# RSS_CTRL register map
Vendor: Texas Instruments
Peripheral module from a debugger description file (folder awr29xx).
Registers are 32-bit, read-only, no defined reset value unless marked. A register's access mark holds for its fields unless they carry their own. Offsets are as the file gives them; lines under a group give offsets from that group; [hi:lo] are bit positions; {n}, {i} and the like mark numbered series; 'fields as' and 'values as' point back to an identical list; <NAME> marks a mode.

## RSS_CTRL
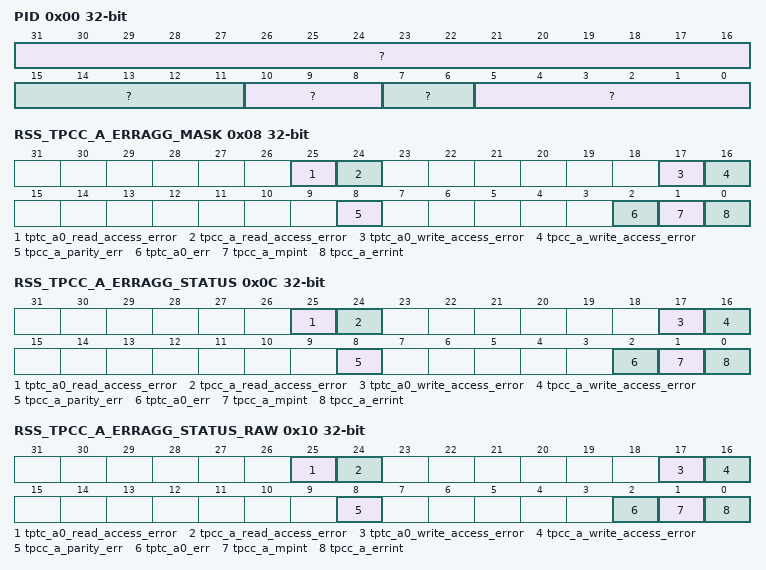
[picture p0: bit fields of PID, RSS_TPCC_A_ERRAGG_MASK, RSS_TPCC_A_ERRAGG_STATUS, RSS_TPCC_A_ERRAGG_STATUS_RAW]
0x00 PID
  [31:16] ?, [15:11] ?, [10:8] ?, [7:6] ?, [5:0] ?
0x08 RSS_TPCC_A_ERRAGG_MASK rw
  [25] tptc_a0_read_access_error, [24] tpcc_a_read_access_error, [17] tptc_a0_write_access_error, [16] tpcc_a_write_access_error, [8] tpcc_a_parity_err, [2] tptc_a0_err, [1] tpcc_a_mpint, [0] tpcc_a_errint
0x0C RSS_TPCC_A_ERRAGG_STATUS rw
  fields as RSS_TPCC_A_ERRAGG_MASK
0x10 RSS_TPCC_A_ERRAGG_STATUS_RAW rw
  fields as RSS_TPCC_A_ERRAGG_MASK
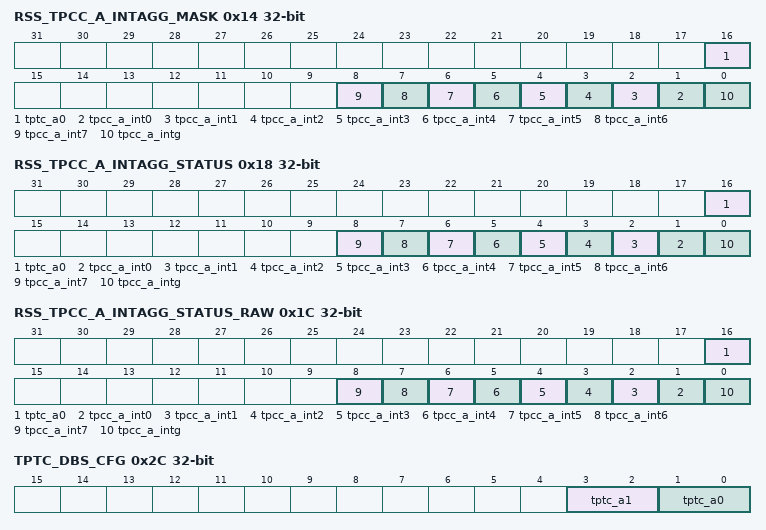
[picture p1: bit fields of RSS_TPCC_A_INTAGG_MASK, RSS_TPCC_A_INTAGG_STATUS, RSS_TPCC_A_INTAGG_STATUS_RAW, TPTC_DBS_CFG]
0x14 RSS_TPCC_A_INTAGG_MASK rw
  [16] tptc_a0 — Mask Interrupt from TPTC A0 to aggregated Interrupt RCSS_TPCC_A_INTAGG 1 : Interrupt is Masked 0 : Interrupt is Unmasked
  [n+1] tpcc_a_int{n} (n=0..7)
  [0] tpcc_a_intg
0x18 RSS_TPCC_A_INTAGG_STATUS rw
  [16] tptc_a0 — Status of Interrupt from TPTC A0. Set only if Interupt is unmasked in RCSS_TPCC_A_INTAGG_MASK Wrie 0x1 to clear this interrupt.
  [n+1] tpcc_a_int{n} (n=0..7)
  [0] tpcc_a_intg
0x1C RSS_TPCC_A_INTAGG_STATUS_RAW rw
  [16] tptc_a0 — Raw Status of Interrupt from TPTC A0. Set irrespective if the Interupt is masked or unmasked in RCSS_TPCC_A_INTAGG_MASK
  [n+1] tpcc_a_int{n} (n=0..7)
  [0] tpcc_a_intg
0x20 RSS_TPCC_MEMINIT_START rw
  [0] tpcc_a_meminit_start — Start Memory intialization of memory. Write 0x1 to start memory initilization. Write 0x0 after ensuring Memory intilization is in progress or has completed.
0x24 RSS_TPCC_MEMINIT_DONE rw
  [0] tpcc_a_meminit_done — Status field. Read value 0x1 indicates previously triggered Memory intialization of memory is complte. Write 0x1 to clear status.
0x28 RSS_TPCC_MEMINIT_STATUS
  [0] tpcc_a_meminit_status — Status field. Read value 0x1 indicates previously triggered Memory intialization of memory is in progress.
0x2C TPTC_DBS_CFG rw
  [3:2] tptc_a1 — Max Burst size tieoff value for TPTC A1
  [1:0] tptc_a0 — Max Burst size tieoff value for TPTC A0
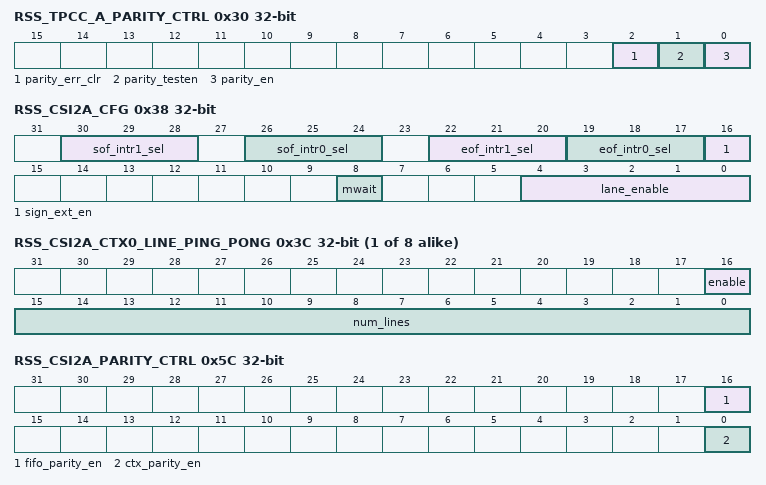
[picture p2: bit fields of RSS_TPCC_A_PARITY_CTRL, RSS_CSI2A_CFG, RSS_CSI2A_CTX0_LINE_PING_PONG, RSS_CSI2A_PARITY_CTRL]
0x30 RSS_TPCC_A_PARITY_CTRL rw
  [2] parity_err_clr — Write 0x1 to clear the Parit Error status for TPCC
  [1] parity_testen — Enable Parity Test for TPCC. Write 0x1 : Parity Test is enabled on PARAM memory
  [0] parity_en — Enable Parity for TPCC. Write 0x1 : Parity is enabled on PARAM memory
0x34 RSS_TPCC_A_PARITY_STATUS
  [15:8] parity_addr — TPCC Error Address at which Parity Error occurred
0x38 RSS_CSI2A_CFG rw
  [30:28] sof_intr1_sel — Select the Start of Frame Contx to be sent as RCSS_CSI2A_SOF_INT1 Write 0 : Start of Frame for Context 0 will be propagated on this interrupt line Write 7 : Start of Frame for Context 7 will be propagated on this interrupt line
  [26:24] sof_intr0_sel — Select the Start of Frame Contx to be sent as RCSS_CSI2A_SOF_INT0 Write 0 : Start of Frame for Context 0 will be propagated on this interrupt line Write 7 : Start of Frame for Context 7 will be propagated on this interrupt line
  [22:20] eof_intr1_sel — Select the End of Frame Contx to be sent as RCSS_CSI2A_EOF_INT1 Write 0 : Start of Frame for Context 0 will be propagated on this interrupt line Write 7 : Start of Frame for Context 7 will be propagated on this interrupt line
  [19:17] eof_intr0_sel — Select the End of Frame Contx to be sent as RCSS_CSI2A_EOF_INT0 Write 0 : Start of Frame for Context 0 will be propagated on this interrupt line Write 7 : Start of Frame for Context 7 will be propagated on this interrupt line
  [16] sign_ext_en — Sign Extention Enable for CSI2 A
  [8] mwait — Power Idle Protocol related Mwait Port
  [4:0] lane_enable — Lane enable for CSI2 A
{0x3C+4i} RSS_CSI2A_CTX{i}_LINE_PING_PONG rw (i=0..7)
  [16] enable — Enable line based ping pong toggle for Context {i} 0 : Diabled 1:Enabled
  [15:0] num_lines — Configure the number of lines for ping pong toggle for Context {i}
0x5C RSS_CSI2A_PARITY_CTRL rw
  [16] fifo_parity_en — Enable Parity for CSI2 FIFO Memory. Write 0x1 : Parity is enabled
  [0] ctx_parity_en — Enable Parity for CSI2 CTX Memory. Write 0x1 : Parity is enabled
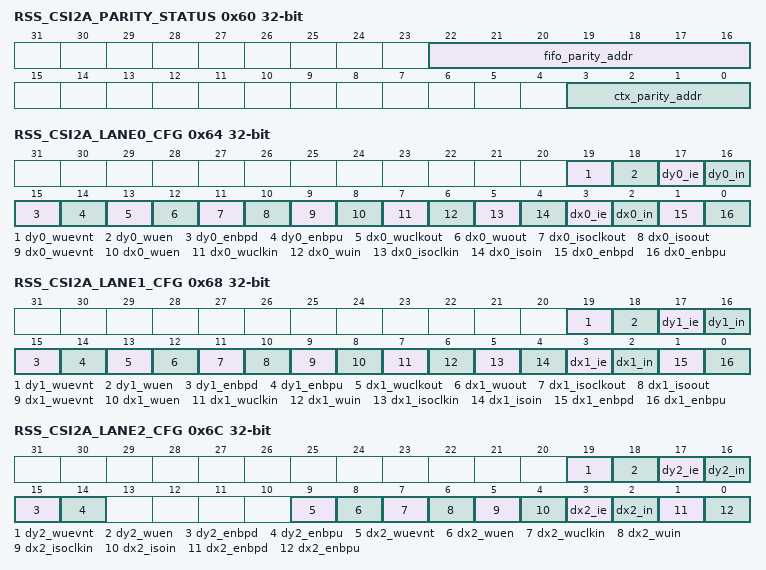
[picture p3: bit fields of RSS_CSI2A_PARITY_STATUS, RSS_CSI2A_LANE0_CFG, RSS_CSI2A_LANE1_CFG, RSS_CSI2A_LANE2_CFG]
0x60 RSS_CSI2A_PARITY_STATUS
  [22:16] fifo_parity_addr — CSI2 FIFO Memory Error Address at which Parity Error occurred
  [3:0] ctx_parity_addr — CSI2 CTX Memory Error Address at which Parity Error occurred
0x64 RSS_CSI2A_LANE0_CFG access per field
  [19] dy0_wuevnt ro — Pad DY Wakeup Event
  [18] dy0_wuen rw — Pad DY Wakeup Enable
  [17] dy0_ie rw — Pad DY Input Buffer Enable
  [16] dy0_in ro — Pad DY Input
  [15] dy0_enbpd rw — Pad DY Enable Pull Down
  [14] dy0_enbpu rw — Pad DY Enable Pull Up
  [13] dx0_wuclkout ro — Pad DX Wakeup Clkout
  [12] dx0_wuout ro — Pad DX Wakeup Output
  [11] dx0_isoclkout ro — Pad DX Isosaltion Clkout
  [10] dx0_isoout ro — Pad DX Isosaltion Output
  [9] dx0_wuevnt ro — Pad DX Wakeup Event
  [8] dx0_wuen rw — Pad DX Wakeup Enable
  [7] dx0_wuclkin rw — Pad DX Wakeup Clkin
  [6] dx0_wuin rw — Pad DX Wakeup Input
  [5] dx0_isoclkin rw — Pad DX Isolation Clkin
  [4] dx0_isoin rw — Pad DX Isosaltion Input
  [3] dx0_ie rw — Pad DX Input Buffer Enable
  [2] dx0_in ro — Pad DX Input
  [1] dx0_enbpd rw — Pad DX Enable Pull Down
  [0] dx0_enbpu rw — Pad DX Enable Pull Up
0x68 RSS_CSI2A_LANE1_CFG access per field
  [19] dy1_wuevnt ro — Pad DY Wakeup Event
  [18] dy1_wuen rw — Pad DY Wakeup Enable
  [17] dy1_ie rw — Pad DY Input Buffer Enable
  [16] dy1_in ro — Pad DY Input
  [15] dy1_enbpd rw — Pad DY Enable Pull Down
  [14] dy1_enbpu rw — Pad DY Enable Pull Up
  [13] dx1_wuclkout ro — Pad DX Wakeup Clkout
  [12] dx1_wuout ro — Pad DX Wakeup Output
  [11] dx1_isoclkout ro — Pad DX Isosaltion Clkout
  [10] dx1_isoout ro — Pad DX Isosaltion Output
  [9] dx1_wuevnt ro — Pad DX Wakeup Event
  [8] dx1_wuen rw — Pad DX Wakeup Enable
  [7] dx1_wuclkin rw — Pad DX Wakeup Clkin
  [6] dx1_wuin rw — Pad DX Wakeup Input
  [5] dx1_isoclkin rw — Pad DX Isolation Clkin
  [4] dx1_isoin rw — Pad DX Isosaltion Input
  [3] dx1_ie rw — Pad DX Input Buffer Enable
  [2] dx1_in ro — Pad DX Input
  [1] dx1_enbpd rw — Pad DX Enable Pull Down
  [0] dx1_enbpu rw — Pad DX Enable Pull Up
0x6C RSS_CSI2A_LANE2_CFG access per field
  [19] dy2_wuevnt ro — Pad DY Wakeup Event
  [18] dy2_wuen rw — Pad DY Wakeup Enable
  [17] dy2_ie rw — Pad DY Input Buffer Enable
  [16] dy2_in ro — Pad DY Input
  [15] dy2_enbpd rw — Pad DY Enable Pull Down
  [14] dy2_enbpu rw — Pad DY Enable Pull Up
  [9] dx2_wuevnt ro — Pad DX Wakeup Event
  [8] dx2_wuen rw — Pad DX Wakeup Enable
  [7] dx2_wuclkin rw — Pad DX Wakeup Clkin
  [6] dx2_wuin rw — Pad DX Wakeup Input
  [5] dx2_isoclkin rw — Pad DX Isolation Clkin
  [4] dx2_isoin rw — Pad DX Isosaltion Input
  [3] dx2_ie rw — Pad DX Input Buffer Enable
  [2] dx2_in ro — Pad DX Input
  [1] dx2_enbpd rw — Pad DX Enable Pull Down
  [0] dx2_enbpu rw — Pad DX Enable Pull Up
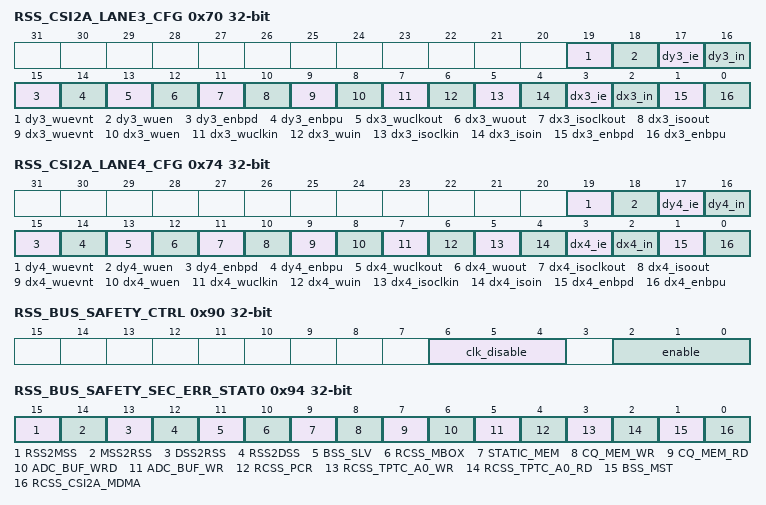
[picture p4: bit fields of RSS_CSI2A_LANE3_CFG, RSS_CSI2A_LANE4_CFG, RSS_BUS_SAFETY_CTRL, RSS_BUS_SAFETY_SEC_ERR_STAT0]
0x70 RSS_CSI2A_LANE3_CFG access per field
  [19] dy3_wuevnt ro — Pad DY Wakeup Event
  [18] dy3_wuen rw — Pad DY Wakeup Enable
  [17] dy3_ie rw — Pad DY Input Buffer Enable
  [16] dy3_in ro — Pad DY Input
  [15] dy3_enbpd rw — Pad DY Enable Pull Down
  [14] dy3_enbpu rw — Pad DY Enable Pull Up
  [13] dx3_wuclkout ro — Pad DX Wakeup Clkout
  [12] dx3_wuout ro — Pad DX Wakeup Output
  [11] dx3_isoclkout ro — Pad DX Isosaltion Clkout
  [10] dx3_isoout ro — Pad DX Isosaltion Output
  [9] dx3_wuevnt ro — Pad DX Wakeup Event
  [8] dx3_wuen rw — Pad DX Wakeup Enable
  [7] dx3_wuclkin rw — Pad DX Wakeup Clkin
  [6] dx3_wuin rw — Pad DX Wakeup Input
  [5] dx3_isoclkin rw — Pad DX Isolation Clkin
  [4] dx3_isoin rw — Pad DX Isosaltion Input
  [3] dx3_ie rw — Pad DX Input Buffer Enable
  [2] dx3_in ro — Pad DX Input
  [1] dx3_enbpd rw — Pad DX Enable Pull Down
  [0] dx3_enbpu rw — Pad DX Enable Pull Up
0x74 RSS_CSI2A_LANE4_CFG access per field
  [19] dy4_wuevnt ro — Pad DY Wakeup Event
  [18] dy4_wuen rw — Pad DY Wakeup Enable
  [17] dy4_ie rw — Pad DY Input Buffer Enable
  [16] dy4_in ro — Pad DY Input
  [15] dy4_enbpd rw — Pad DY Enable Pull Down
  [14] dy4_enbpu rw — Pad DY Enable Pull Up
  [13] dx4_wuclkout ro — Pad DX Wakeup Clkout
  [12] dx4_wuout ro — Pad DX Wakeup Output
  [11] dx4_isoclkout ro — Pad DX Isosaltion Clkout
  [10] dx4_isoout ro — Pad DX Isosaltion Output
  [9] dx4_wuevnt ro — Pad DX Wakeup Event
  [8] dx4_wuen rw — Pad DX Wakeup Enable
  [7] dx4_wuclkin rw — Pad DX Wakeup Clkin
  [6] dx4_wuin rw — Pad DX Wakeup Input
  [5] dx4_isoclkin rw — Pad DX Isolation Clkin
  [4] dx4_isoin rw — Pad DX Isosaltion Input
  [3] dx4_ie rw — Pad DX Input Buffer Enable
  [2] dx4_in ro — Pad DX Input
  [1] dx4_enbpd rw — Pad DX Enable Pull Down
  [0] dx4_enbpu rw — Pad DX Enable Pull Up
0x78 RSS_CSI2A_FIFO_MEMINIT rw
  [0] start — Start Memory intialization of memory. Write 0x1 to start memory initilization. Write 0x0 after ensuring Memory intilization is in progress or has completed.
0x7C RSS_CSI2A_FIFO_MEMINIT_DONE rw
  [0] done — Status field. Read value 0x1 indicates previously triggered Memory intialization of memory is complte. Write 0x1 to clear status.
0x80 RSS_CSI2A_FIFO_MEMINIT_STATUS
  [0] status — Status field. Read value 0x1 indicates previously triggered Memory intialization of memory is in progress.
0x84 RSS_CSI2A_CTX_MEMINIT rw
  fields as RSS_CSI2A_FIFO_MEMINIT
0x88 RSS_CSI2A_CTX_MEMINIT_DONE rw
  fields as RSS_CSI2A_FIFO_MEMINIT_DONE
0x8C RSS_CSI2A_CTX_MEMINIT_STATUS
  fields as RSS_CSI2A_FIFO_MEMINIT_STATUS
0x90 RSS_BUS_SAFETY_CTRL rw
  [6:4] clk_disable — Option to clock gate the safety infrastructure is Safety is disabled
  [2:0] enable — Refer to TPR12 Substem Microarch document for more details
0x94 RSS_BUS_SAFETY_SEC_ERR_STAT0
  [15] RSS2MSS — Refer to TPR12 Substem Microarch document for more details
  [14] MSS2RSS — Refer to TPR12 Substem Microarch document for more details
  [13] DSS2RSS — Refer to TPR12 Substem Microarch document for more details
  [12] RSS2DSS — Refer to TPR12 Substem Microarch document for more details
  [11] BSS_SLV — Refer to TPR12 Substem Microarch document for more details
  [10] RCSS_MBOX — Refer to TPR12 Substem Microarch document for more details
  [9] STATIC_MEM — Refer to TPR12 Substem Microarch document for more details
  [8] CQ_MEM_WR — Refer to TPR12 Substem Microarch document for more details
  [7] CQ_MEM_RD — Refer to TPR12 Substem Microarch document for more details
  [6] ADC_BUF_WRD — Refer to TPR12 Substem Microarch document for more details
  [5] ADC_BUF_WR — Refer to TPR12 Substem Microarch document for more details
  [4] RCSS_PCR — Refer to TPR12 Substem Microarch document for more details
  [3] RCSS_TPTC_A0_WR — Refer to TPR12 Substem Microarch document for more details
  [2] RCSS_TPTC_A0_RD — Refer to TPR12 Substem Microarch document for more details
  [1] BSS_MST — Refer to TPR12 Substem Microarch document for more details
  [0] RCSS_CSI2A_MDMA — Refer to TPR12 Substem Microarch document for more details
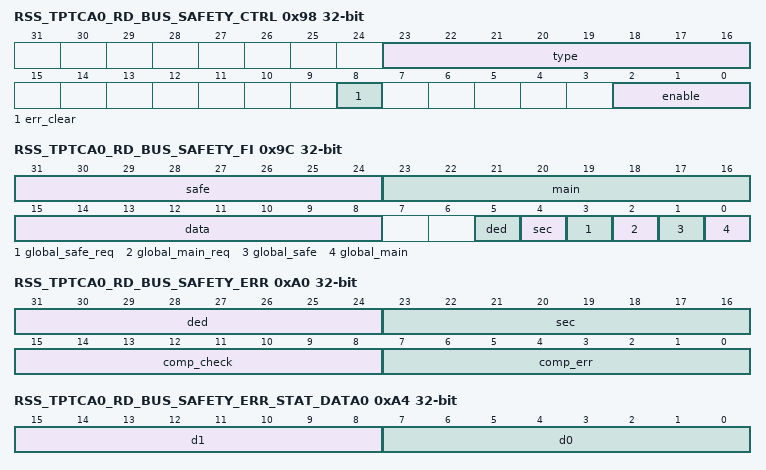
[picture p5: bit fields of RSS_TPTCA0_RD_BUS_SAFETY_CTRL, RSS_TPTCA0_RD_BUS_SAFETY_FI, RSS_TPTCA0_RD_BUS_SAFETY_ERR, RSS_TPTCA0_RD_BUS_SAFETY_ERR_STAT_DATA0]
0x98 RSS_TPTCA0_RD_BUS_SAFETY_CTRL access per field
  [23:16] type ro — Refer to TPR12 Substem Microarch document for more details
  [8] err_clear rw — Refer to TPR12 Substem Microarch document for more details
  [2:0] enable rw — Refer to TPR12 Substem Microarch document for more details
0x9C RSS_TPTCA0_RD_BUS_SAFETY_FI rw
  [31:24] safe — Refer to TPR12 Substem Microarch document for more details
  [23:16] main — Refer to TPR12 Substem Microarch document for more details
  [15:8] data — Refer to TPR12 Substem Microarch document for more details
  [5] ded — Refer to TPR12 Substem Microarch document for more details
  [4] sec — Refer to TPR12 Substem Microarch document for more details
  [3] global_safe_req — Refer to TPR12 Substem Microarch document for more details
  [2] global_main_req — Refer to TPR12 Substem Microarch document for more details
  [1] global_safe — Refer to TPR12 Substem Microarch document for more details
  [0] global_main — Refer to TPR12 Substem Microarch document for more details
0xA0 RSS_TPTCA0_RD_BUS_SAFETY_ERR
  [31:24] ded — Refer to TPR12 Substem Microarch document for more details
  [23:16] sec — Refer to TPR12 Substem Microarch document for more details
  [15:8] comp_check — Refer to TPR12 Substem Microarch document for more details
  [7:0] comp_err — Refer to TPR12 Substem Microarch document for more details
0xA4 RSS_TPTCA0_RD_BUS_SAFETY_ERR_STAT_DATA0
  [15:8] d1 — Refer to TPR12 Substem Microarch document for more details
  [7:0] d0 — Refer to TPR12 Substem Microarch document for more details
0xA8 RSS_TPTCA0_RD_BUS_SAFETY_ERR_STAT_CMD
  [31:0] stat — Refer to TPR12 Substem Microarch document for more details
0xAC RSS_TPTCA0_RD_BUS_SAFETY_ERR_STAT_READ
  fields as RSS_TPTCA0_RD_BUS_SAFETY_ERR_STAT_CMD
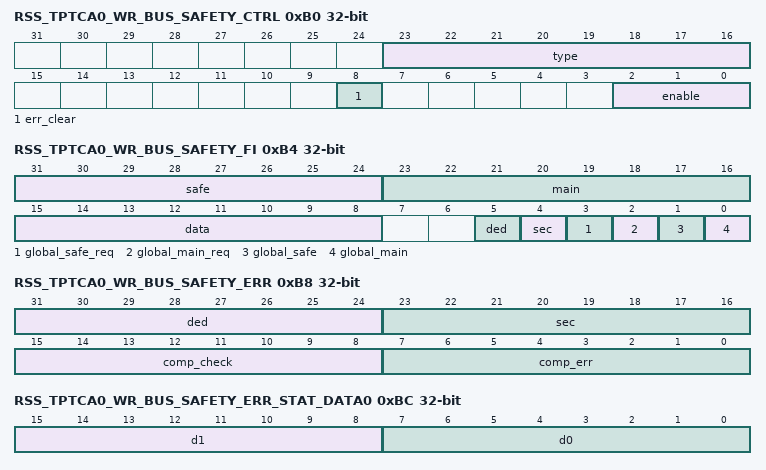
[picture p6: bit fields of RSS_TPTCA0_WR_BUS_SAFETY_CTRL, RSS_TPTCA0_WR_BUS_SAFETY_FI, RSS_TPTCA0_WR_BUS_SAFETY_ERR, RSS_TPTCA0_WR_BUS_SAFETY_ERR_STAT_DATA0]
0xB0 RSS_TPTCA0_WR_BUS_SAFETY_CTRL access per field
  fields as RSS_TPTCA0_RD_BUS_SAFETY_CTRL
0xB4 RSS_TPTCA0_WR_BUS_SAFETY_FI rw
  fields as RSS_TPTCA0_RD_BUS_SAFETY_FI
0xB8 RSS_TPTCA0_WR_BUS_SAFETY_ERR
  fields as RSS_TPTCA0_RD_BUS_SAFETY_ERR
0xBC RSS_TPTCA0_WR_BUS_SAFETY_ERR_STAT_DATA0
  fields as RSS_TPTCA0_RD_BUS_SAFETY_ERR_STAT_DATA0
0xC0 RSS_TPTCA0_WR_BUS_SAFETY_ERR_STAT_CMD
  fields as RSS_TPTCA0_RD_BUS_SAFETY_ERR_STAT_CMD
0xC4 RSS_TPTCA0_WR_BUS_SAFETY_ERR_STAT_WRITE
  fields as RSS_TPTCA0_RD_BUS_SAFETY_ERR_STAT_CMD
0xC8 RSS_TPTCA0_WR_BUS_SAFETY_ERR_STAT_WRITERESP
  fields as RSS_TPTCA0_RD_BUS_SAFETY_ERR_STAT_CMD
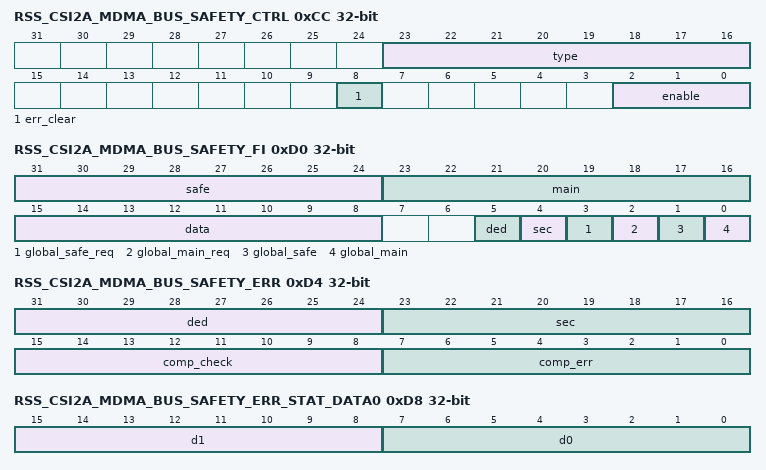
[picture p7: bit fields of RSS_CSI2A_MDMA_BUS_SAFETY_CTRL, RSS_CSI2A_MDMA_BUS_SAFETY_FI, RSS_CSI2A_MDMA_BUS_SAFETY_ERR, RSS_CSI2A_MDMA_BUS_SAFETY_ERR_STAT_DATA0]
0xCC RSS_CSI2A_MDMA_BUS_SAFETY_CTRL access per field
  fields as RSS_TPTCA0_RD_BUS_SAFETY_CTRL
0xD0 RSS_CSI2A_MDMA_BUS_SAFETY_FI rw
  fields as RSS_TPTCA0_RD_BUS_SAFETY_FI
0xD4 RSS_CSI2A_MDMA_BUS_SAFETY_ERR
  fields as RSS_TPTCA0_RD_BUS_SAFETY_ERR
0xD8 RSS_CSI2A_MDMA_BUS_SAFETY_ERR_STAT_DATA0
  fields as RSS_TPTCA0_RD_BUS_SAFETY_ERR_STAT_DATA0
0xDC RSS_CSI2A_MDMA_BUS_SAFETY_ERR_STAT_CMD
  fields as RSS_TPTCA0_RD_BUS_SAFETY_ERR_STAT_CMD
0xE0 RSS_CSI2A_MDMA_BUS_SAFETY_ERR_STAT_WRITE
  fields as RSS_TPTCA0_RD_BUS_SAFETY_ERR_STAT_CMD
0xE4 RSS_CSI2A_MDMA_BUS_SAFETY_ERR_STAT_READ
  fields as RSS_TPTCA0_RD_BUS_SAFETY_ERR_STAT_CMD
0xE8 RSS_CSI2A_MDMA_BUS_SAFETY_ERR_STAT_WRITERESP
  fields as RSS_TPTCA0_RD_BUS_SAFETY_ERR_STAT_CMD
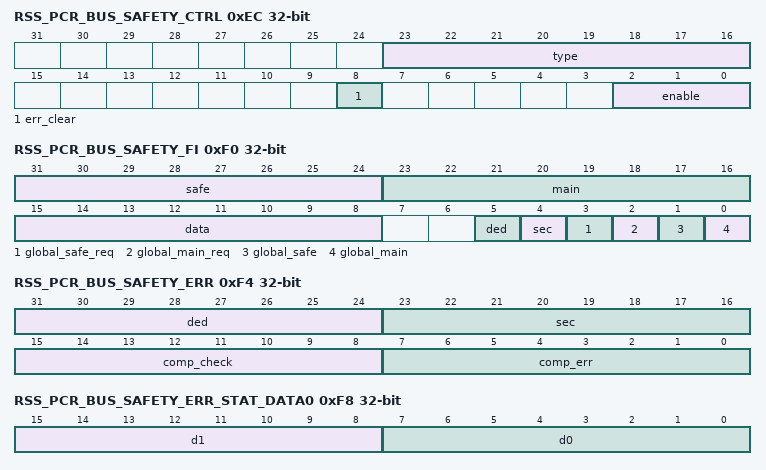
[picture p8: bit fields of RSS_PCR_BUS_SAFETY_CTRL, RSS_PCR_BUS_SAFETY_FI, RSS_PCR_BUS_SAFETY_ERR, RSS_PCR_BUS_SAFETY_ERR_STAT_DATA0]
0xEC RSS_PCR_BUS_SAFETY_CTRL access per field
  fields as RSS_TPTCA0_RD_BUS_SAFETY_CTRL
0xF0 RSS_PCR_BUS_SAFETY_FI rw
  fields as RSS_TPTCA0_RD_BUS_SAFETY_FI
0xF4 RSS_PCR_BUS_SAFETY_ERR
  fields as RSS_TPTCA0_RD_BUS_SAFETY_ERR
0xF8 RSS_PCR_BUS_SAFETY_ERR_STAT_DATA0
  fields as RSS_TPTCA0_RD_BUS_SAFETY_ERR_STAT_DATA0
0xFC RSS_PCR_BUS_SAFETY_ERR_STAT_CMD
  fields as RSS_TPTCA0_RD_BUS_SAFETY_ERR_STAT_CMD
0x100 RSS_PCR_BUS_SAFETY_ERR_STAT_WRITE
  fields as RSS_TPTCA0_RD_BUS_SAFETY_ERR_STAT_CMD
0x104 RSS_PCR_BUS_SAFETY_ERR_STAT_READ
  fields as RSS_TPTCA0_RD_BUS_SAFETY_ERR_STAT_CMD
0x108 RSS_PCR_BUS_SAFETY_ERR_STAT_WRITERESP
  fields as RSS_TPTCA0_RD_BUS_SAFETY_ERR_STAT_CMD
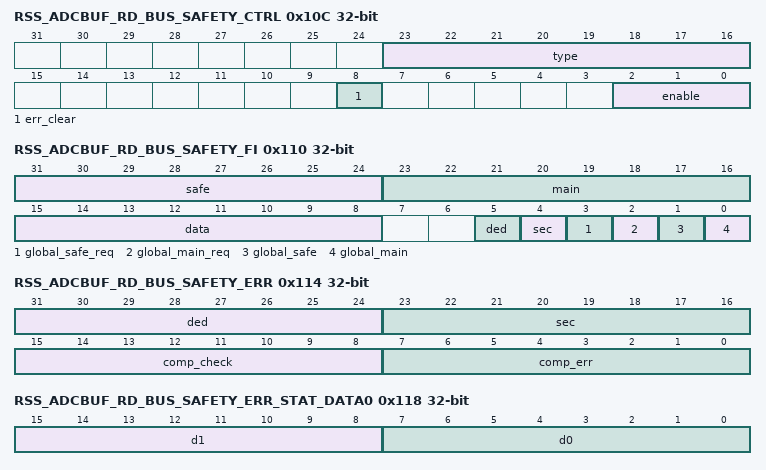
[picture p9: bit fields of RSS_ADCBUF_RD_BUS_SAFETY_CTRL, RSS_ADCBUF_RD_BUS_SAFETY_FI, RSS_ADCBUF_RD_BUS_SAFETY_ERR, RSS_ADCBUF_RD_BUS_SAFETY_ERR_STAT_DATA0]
0x10C RSS_ADCBUF_RD_BUS_SAFETY_CTRL access per field
  fields as RSS_TPTCA0_RD_BUS_SAFETY_CTRL
0x110 RSS_ADCBUF_RD_BUS_SAFETY_FI rw
  fields as RSS_TPTCA0_RD_BUS_SAFETY_FI
0x114 RSS_ADCBUF_RD_BUS_SAFETY_ERR
  fields as RSS_TPTCA0_RD_BUS_SAFETY_ERR
0x118 RSS_ADCBUF_RD_BUS_SAFETY_ERR_STAT_DATA0
  fields as RSS_TPTCA0_RD_BUS_SAFETY_ERR_STAT_DATA0
0x11C RSS_ADCBUF_RD_BUS_SAFETY_ERR_STAT_CMD
  fields as RSS_TPTCA0_RD_BUS_SAFETY_ERR_STAT_CMD
0x120 RSS_ADCBUF_RD_BUS_SAFETY_ERR_STAT_READ
  fields as RSS_TPTCA0_RD_BUS_SAFETY_ERR_STAT_CMD
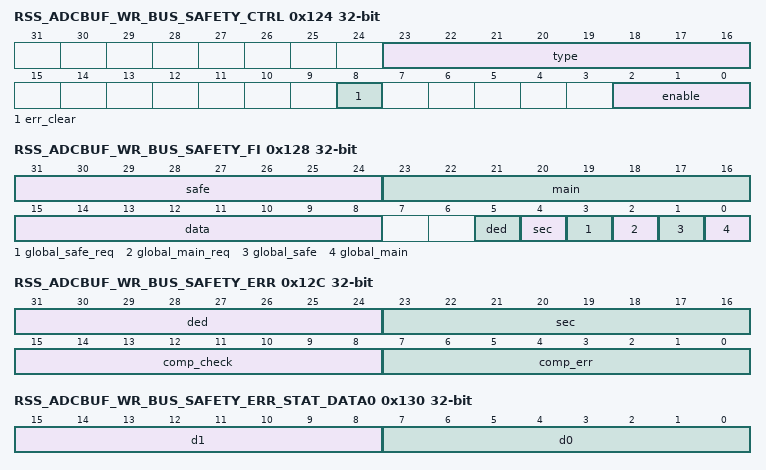
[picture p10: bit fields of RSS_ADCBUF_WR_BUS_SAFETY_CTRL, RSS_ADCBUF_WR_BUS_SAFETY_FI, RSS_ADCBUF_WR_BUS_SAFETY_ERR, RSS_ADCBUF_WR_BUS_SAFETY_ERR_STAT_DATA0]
0x124 RSS_ADCBUF_WR_BUS_SAFETY_CTRL access per field
  fields as RSS_TPTCA0_RD_BUS_SAFETY_CTRL
0x128 RSS_ADCBUF_WR_BUS_SAFETY_FI rw
  fields as RSS_TPTCA0_RD_BUS_SAFETY_FI
0x12C RSS_ADCBUF_WR_BUS_SAFETY_ERR
  fields as RSS_TPTCA0_RD_BUS_SAFETY_ERR
0x130 RSS_ADCBUF_WR_BUS_SAFETY_ERR_STAT_DATA0
  fields as RSS_TPTCA0_RD_BUS_SAFETY_ERR_STAT_DATA0
0x134 RSS_ADCBUF_WR_BUS_SAFETY_ERR_STAT_CMD
  fields as RSS_TPTCA0_RD_BUS_SAFETY_ERR_STAT_CMD
0x138 RSS_ADCBUF_WR_BUS_SAFETY_ERR_STAT_WRITE
  fields as RSS_TPTCA0_RD_BUS_SAFETY_ERR_STAT_CMD
0x13C RSS_ADCBUF_WR_BUS_SAFETY_ERR_STAT_WRITERESP
  fields as RSS_TPTCA0_RD_BUS_SAFETY_ERR_STAT_CMD
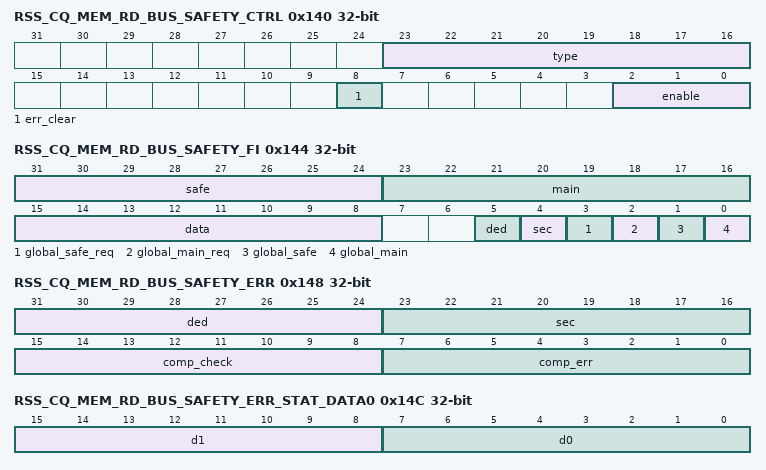
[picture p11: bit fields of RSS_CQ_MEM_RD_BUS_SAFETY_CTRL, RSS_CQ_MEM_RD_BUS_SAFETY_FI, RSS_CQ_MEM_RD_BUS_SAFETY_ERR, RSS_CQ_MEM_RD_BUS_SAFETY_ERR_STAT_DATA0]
0x140 RSS_CQ_MEM_RD_BUS_SAFETY_CTRL access per field
  fields as RSS_TPTCA0_RD_BUS_SAFETY_CTRL
0x144 RSS_CQ_MEM_RD_BUS_SAFETY_FI rw
  fields as RSS_TPTCA0_RD_BUS_SAFETY_FI
0x148 RSS_CQ_MEM_RD_BUS_SAFETY_ERR
  fields as RSS_TPTCA0_RD_BUS_SAFETY_ERR
0x14C RSS_CQ_MEM_RD_BUS_SAFETY_ERR_STAT_DATA0
  fields as RSS_TPTCA0_RD_BUS_SAFETY_ERR_STAT_DATA0
0x150 RSS_CQ_MEM_RD_BUS_SAFETY_ERR_STAT_CMD
  fields as RSS_TPTCA0_RD_BUS_SAFETY_ERR_STAT_CMD
0x154 RSS_CQ_MEM_RD_BUS_SAFETY_ERR_STAT_READ
  fields as RSS_TPTCA0_RD_BUS_SAFETY_ERR_STAT_CMD
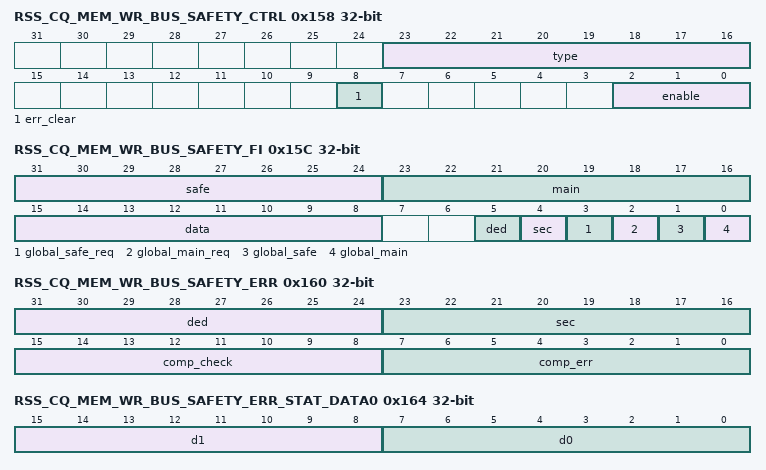
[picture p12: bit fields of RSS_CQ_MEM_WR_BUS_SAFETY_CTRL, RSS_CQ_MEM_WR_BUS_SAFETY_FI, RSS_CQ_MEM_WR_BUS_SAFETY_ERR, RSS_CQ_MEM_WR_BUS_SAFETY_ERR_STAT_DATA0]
0x158 RSS_CQ_MEM_WR_BUS_SAFETY_CTRL access per field
  fields as RSS_TPTCA0_RD_BUS_SAFETY_CTRL
0x15C RSS_CQ_MEM_WR_BUS_SAFETY_FI rw
  fields as RSS_TPTCA0_RD_BUS_SAFETY_FI
0x160 RSS_CQ_MEM_WR_BUS_SAFETY_ERR
  fields as RSS_TPTCA0_RD_BUS_SAFETY_ERR
0x164 RSS_CQ_MEM_WR_BUS_SAFETY_ERR_STAT_DATA0
  fields as RSS_TPTCA0_RD_BUS_SAFETY_ERR_STAT_DATA0
0x168 RSS_CQ_MEM_WR_BUS_SAFETY_ERR_STAT_CMD
  fields as RSS_TPTCA0_RD_BUS_SAFETY_ERR_STAT_CMD
0x16C RSS_CQ_MEM_WR_BUS_SAFETY_ERR_STAT_WRITE
  fields as RSS_TPTCA0_RD_BUS_SAFETY_ERR_STAT_CMD
0x170 RSS_CQ_MEM_WR_BUS_SAFETY_ERR_STAT_WRITERESP
  fields as RSS_TPTCA0_RD_BUS_SAFETY_ERR_STAT_CMD
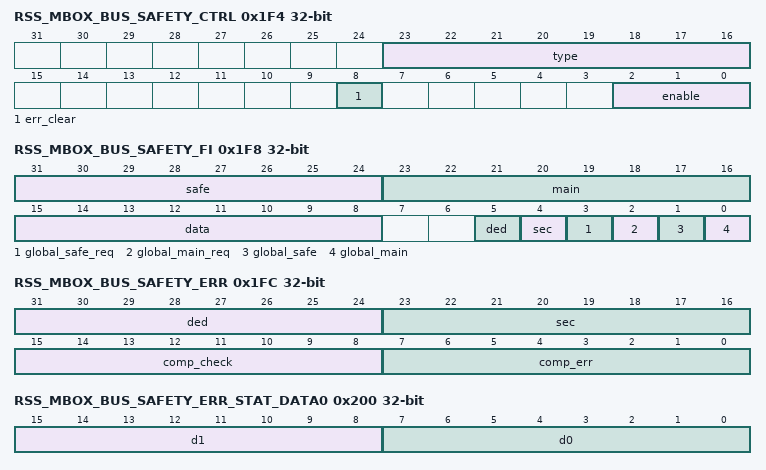
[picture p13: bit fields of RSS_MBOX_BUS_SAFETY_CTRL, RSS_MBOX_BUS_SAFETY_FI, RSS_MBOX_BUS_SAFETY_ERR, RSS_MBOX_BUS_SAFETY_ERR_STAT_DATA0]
0x1F4 RSS_MBOX_BUS_SAFETY_CTRL access per field
  fields as RSS_TPTCA0_RD_BUS_SAFETY_CTRL
0x1F8 RSS_MBOX_BUS_SAFETY_FI rw
  fields as RSS_TPTCA0_RD_BUS_SAFETY_FI
0x1FC RSS_MBOX_BUS_SAFETY_ERR
  fields as RSS_TPTCA0_RD_BUS_SAFETY_ERR
0x200 RSS_MBOX_BUS_SAFETY_ERR_STAT_DATA0
  fields as RSS_TPTCA0_RD_BUS_SAFETY_ERR_STAT_DATA0
0x204 RSS_MBOX_BUS_SAFETY_ERR_STAT_CMD
  fields as RSS_TPTCA0_RD_BUS_SAFETY_ERR_STAT_CMD
0x208 RSS_MBOX_BUS_SAFETY_ERR_STAT_WRITE
  fields as RSS_TPTCA0_RD_BUS_SAFETY_ERR_STAT_CMD
0x20C RSS_MBOX_BUS_SAFETY_ERR_STAT_READ
  fields as RSS_TPTCA0_RD_BUS_SAFETY_ERR_STAT_CMD
0x210 RSS_MBOX_BUS_SAFETY_ERR_STAT_WRITERESP
  fields as RSS_TPTCA0_RD_BUS_SAFETY_ERR_STAT_CMD
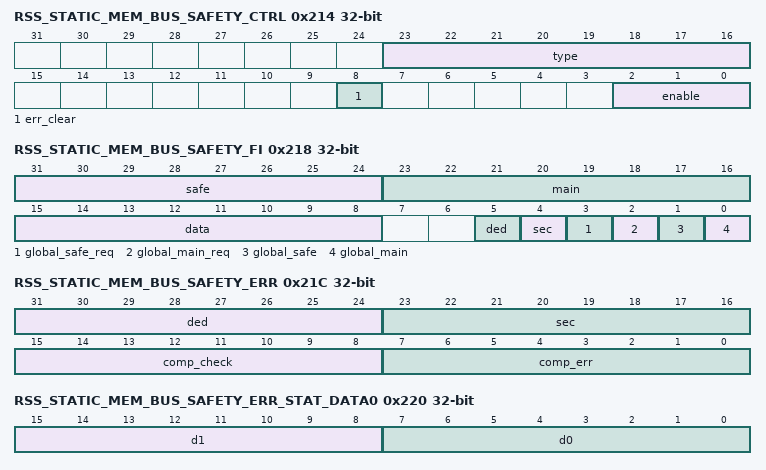
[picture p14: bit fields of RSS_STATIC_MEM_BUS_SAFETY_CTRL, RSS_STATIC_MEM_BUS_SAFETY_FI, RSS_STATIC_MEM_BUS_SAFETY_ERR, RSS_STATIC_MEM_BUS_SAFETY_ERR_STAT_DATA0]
0x214 RSS_STATIC_MEM_BUS_SAFETY_CTRL access per field
  fields as RSS_TPTCA0_RD_BUS_SAFETY_CTRL
0x218 RSS_STATIC_MEM_BUS_SAFETY_FI rw
  fields as RSS_TPTCA0_RD_BUS_SAFETY_FI
0x21C RSS_STATIC_MEM_BUS_SAFETY_ERR
  fields as RSS_TPTCA0_RD_BUS_SAFETY_ERR
0x220 RSS_STATIC_MEM_BUS_SAFETY_ERR_STAT_DATA0
  fields as RSS_TPTCA0_RD_BUS_SAFETY_ERR_STAT_DATA0
0x224 RSS_STATIC_MEM_BUS_SAFETY_ERR_STAT_CMD
  fields as RSS_TPTCA0_RD_BUS_SAFETY_ERR_STAT_CMD
0x228 RSS_STATIC_MEM_BUS_SAFETY_ERR_STAT_WRITE
  fields as RSS_TPTCA0_RD_BUS_SAFETY_ERR_STAT_CMD
0x22C RSS_STATIC_MEM_BUS_SAFETY_ERR_STAT_READ
  fields as RSS_TPTCA0_RD_BUS_SAFETY_ERR_STAT_CMD
0x230 RSS_STATIC_MEM_BUS_SAFETY_ERR_STAT_WRITERESP
  fields as RSS_TPTCA0_RD_BUS_SAFETY_ERR_STAT_CMD
0x234 RSS_BSS_MST_BUS_SAFETY_CTRL access per field
  fields as RSS_TPTCA0_RD_BUS_SAFETY_CTRL
0x238 RSS_BSS_MST_BUS_SAFETY_FI rw
  fields as RSS_TPTCA0_RD_BUS_SAFETY_FI
0x23C RSS_BSS_MST_BUS_SAFETY_ERR
  fields as RSS_TPTCA0_RD_BUS_SAFETY_ERR
0x240 RSS_BSS_MST_BUS_SAFETY_ERR_STAT_DATA0
  fields as RSS_TPTCA0_RD_BUS_SAFETY_ERR_STAT_DATA0
0x244 RSS_BSS_MST_BUS_SAFETY_ERR_STAT_CMD
  fields as RSS_TPTCA0_RD_BUS_SAFETY_ERR_STAT_CMD
0x248 RSS_BSS_MST_BUS_SAFETY_ERR_STAT_WRITE
  fields as RSS_TPTCA0_RD_BUS_SAFETY_ERR_STAT_CMD
0x24C RSS_BSS_MST_BUS_SAFETY_ERR_STAT_READ
  fields as RSS_TPTCA0_RD_BUS_SAFETY_ERR_STAT_CMD
0x250 RSS_BSS_MST_BUS_SAFETY_ERR_STAT_WRITERESP
  fields as RSS_TPTCA0_RD_BUS_SAFETY_ERR_STAT_CMD
0x254 RSS_BSS_SLV_BUS_SAFETY_CTRL access per field
  fields as RSS_TPTCA0_RD_BUS_SAFETY_CTRL
0x258 RSS_BSS_SLV_BUS_SAFETY_FI rw
  fields as RSS_TPTCA0_RD_BUS_SAFETY_FI
0x25C RSS_BSS_SLV_BUS_SAFETY_ERR
  fields as RSS_TPTCA0_RD_BUS_SAFETY_ERR
0x260 RSS_BSS_SLV_BUS_SAFETY_ERR_STAT_DATA0
  fields as RSS_TPTCA0_RD_BUS_SAFETY_ERR_STAT_DATA0
0x264 RSS_BSS_SLV_BUS_SAFETY_ERR_STAT_CMD
  fields as RSS_TPTCA0_RD_BUS_SAFETY_ERR_STAT_CMD
0x268 RSS_BSS_SLV_BUS_SAFETY_ERR_STAT_WRITE
  fields as RSS_TPTCA0_RD_BUS_SAFETY_ERR_STAT_CMD
0x26C RSS_BSS_SLV_BUS_SAFETY_ERR_STAT_READ
  fields as RSS_TPTCA0_RD_BUS_SAFETY_ERR_STAT_CMD
0x270 RSS_BSS_SLV_BUS_SAFETY_ERR_STAT_WRITERESP
  fields as RSS_TPTCA0_RD_BUS_SAFETY_ERR_STAT_CMD
0x274 RSS_TPTC_BOUNDARY_CFG rw
  [5:0] tptc_a0_size — Writing 1'b1 will disable the CID-RID-SID reodering feature for the TPTC instance
0x278 RSS_TPTC_XID_REORDER_CFG rw
  [0] tptc_a0_disable — 6 bit signal used for deciding the boundary crossing size for CID-RID-SID reordering of TPTC Example: writing 6'd19 decidies boundary to be 2^19 i.e. 512 KB
0x27C DBG_ACK_CPU_CTRL rw
  [2:0] sel — Select the Processor Suspend that is used to Suspend the DSS Peripehrals 0:MSS CR5 1:DSP 2:DSS CM4 3-7:RSS CR4
0x280 RSS_ADCBUF_PING_MEMINIT rw
  fields as RSS_CSI2A_FIFO_MEMINIT
0x284 RSS_ADCBUF_PING_MEMINIT_DONE rw
  fields as RSS_CSI2A_FIFO_MEMINIT_DONE
0x288 RSS_ADCBUF_PING_MEMINIT_STATUS
  fields as RSS_CSI2A_FIFO_MEMINIT_STATUS
0x28C RSS_ADCBUF_PONG_MEMINIT rw
  fields as RSS_CSI2A_FIFO_MEMINIT
0x290 RSS_ADCBUF_PONG_MEMINIT_DONE rw
  fields as RSS_CSI2A_FIFO_MEMINIT_DONE
0x294 RSS_ADCBUF_PONG_MEMINIT_STATUS
  fields as RSS_CSI2A_FIFO_MEMINIT_STATUS
0x2C8 SOC_TO_BSS_SW_INT rw
  [7:0] trig — Write Pulse Bit field writing to each bit field <0-7>: 1'b1:triggers BSS_SW_INT_RSS_CTRL<0-7> to BSS
0x2CC RSS_DBG_ACK_CTL0 rw
  [2:0] frc — emulation suspend signal control . Writing '111' would ungate the emulation suspend signal to the FRC
0x2D0 DMMSWINT1 rw
  [22] DMMCQWREN — CQ Write Enable from DMM. 0 --> Write to CQ memory will happen from DFE and Ping-pong select will come from HW FSM (same as ADC Buffer ping-pong select). 1 --> Write to CQ memory will happen from CQ_W slave port in DSS interconnect using DMM as master and Ping-pong select will come from DMMCQPINPONSEL register.
  [21] DMMCQPINPONSEL — CQ Ping Pong select for HIL Mode
  [18] DMMCPWREN — Writiing 1'b1: Enables DMM writes in to CP read registers 1'b0: Disables DMM writes to CP read registers
  [17] DMMADCBUFWREN — ADC Buffer Write Enable from DMM. 0 --> Write to ADC BUF memory will happen from DFE and Ping-pong select will come from HW FSM (same as ADC Buffer ping-pong select). 1 --> Write to CQ memory will happen from ADCBUF_W slave port in DSS interconnect using DMM as master and Ping-pong select will come from DMMADCBUFPINPONSEL register.
  [16] DMMADCBUFPINPONSEL — ADC Buffer Ping Pong select for HIL Mode
0x2D4 RSS_SHARED_MEM_MEMINIT rw
  fields as RSS_CSI2A_FIFO_MEMINIT
0x2D8 RSS_SHARED_MEM_MEMINIT_DONE rw
  fields as RSS_CSI2A_FIFO_MEMINIT_DONE
0x2DC RSS_SHARED_MEM_MEMINIT_STATUS
  fields as RSS_CSI2A_FIFO_MEMINIT_STATUS
0x2E0 RSS_CSI_ACCESS_MODE rw
  [0] csi2a_sel — writing 1'b0 : ensures all the accesses from CSI2A are user-mode writing 1'b1 : ensures all the accesses from CSI2A are privilege mode
0x400 BSS_CONTROL rw
  [30:28] dss_l3_access — writing 3'b111 allocates DSS_L3_BANKD 256KB as TCM for RSS_CR4
  [26:24] halt — writing 3'b000 unhalts BSS. This is expected to be writen only once per processor reset cycle.
  [18:16] wfi_override — writing 3'b111 overrides the WFI signal from CR4 and asserts it.
  [11:0] bootmode — writing 12'h000 : selects the normal boot mode for CR4. 12'h111 : selects the FW dev mode for CR4 12'h222 : selects the orbit mode for CR4 12'h333 : selects the 14xx ROM swap mode
0x404 BSS_TCM_MEMINIT rw
  [0] mem0_init — Start Memory intialization of memory. Write 0x1 to start memory initilization.
0x408 BSS_TCM_MEMINIT_DONE rw
  [0] mem0_done — Status field. Read value 0x1 indicates previously triggered Memory intialization of memory is complte. Write 0x1 to clear status.
0x40C BSS_TCM_MEMINIT_STATUS
  [0] mem0_status — Status field. Read value 0x1 indicates previously triggered Memory intialization of memory is in progress.
0x410 BSS_VIM_MEMINIT rw
  fields as BSS_TCM_MEMINIT
0x414 BSS_VIM_MEMINIT_DONE rw
  fields as BSS_TCM_MEMINIT_DONE
0x418 BSS_VIM_MEMINIT_STATUS
  fields as BSS_TCM_MEMINIT_STATUS
0x41C BSS_DFE_MEMINIT rw
  fields as BSS_TCM_MEMINIT
0x420 BSS_DFE_MEMINIT_DONE rw
  fields as BSS_TCM_MEMINIT_DONE
0x424 BSS_DFE_MEMINIT_STATUS
  fields as BSS_TCM_MEMINIT_STATUS
0x428 BSS_RAMPGEN_MEMINIT rw
  fields as BSS_TCM_MEMINIT
0x42C BSS_RAMPGEN_MEMINIT_DONE rw
  fields as BSS_TCM_MEMINIT_DONE
0x430 BSS_RAMPGEN_MEMINIT_STATUS
  fields as BSS_TCM_MEMINIT_STATUS
0x434 BSS_DSS_L3_STICKY rw
  [2:0] sticky_enable — writing 3'b111 make the BSS_CONTROL::DSS_L3_ACCESS_ENABLE sticky. Further writes to DSS_L3_ACCESS_ENABLE wont impact the register
0x438 BSS_DSS_L3_ACCESS
  [0] status — reading 1'b0: DSS_L3_BANKD1 is not allocated to BSS_TCMA 1'b1: DSS_L3_BANKD1 is allocated to BSS_TCMA
0x800 TESTPATTERNRX1ICFG rw
  [31:16] TSTPATRX1IINCR — Value to be added for each successive sample for the test pattern data in I channel Rx channel 0. In this register the naming convention for the 4 Rx channel indices are from 1 to 4 instead of 0 to 3.
  [15:0] TSTPATRX1IOFFSET — Offset value to be used for the first sample for the test pattern data in I channel Rx channel 0. In this register the naming convention for the 4 Rx channel indices are from 1 to 4 instead of 0 to 3.
0x804 TESTPATTERNRX2ICFG rw
  [31:16] TSTPATRX2IINCR — Value to be added for each successive sample for the test pattern data in I channel Rx channel 1.
  [15:0] TSTPATRX2IOFFSET — Offset value to be used for the first sample for the test pattern data in I channel Rx channel 1.
0x808 TESTPATTERNRX3ICFG rw
  [31:16] TSTPATRX3IINCR — Value to be added for each successive sample for the test pattern data in I channel Rx channel 2
  [15:0] TSTPATRX3IOFFSET — Offset value to be used for the first sample for the test pattern data in I channel Rx channel 2
0x80C TESTPATTERNRX4ICFG rw
  [31:16] TSTPATRX4IINCR — Value to be added for each successive sample for the test pattern data in I channel Rx channel 3
  [15:0] TSTPATRX4IOFFSET — Offset value to be used for the first sample for the test pattern data in I channel Rx channel 3
0x810 TESTPATTERNRX1QCFG rw
  [31:16] TSTPATRX1QINCR — Value to be added for each successive sample for the test pattern data in Q channel Rx channel 0. In this register the naming convention for the 4 Rx channel indices are from 1 to 4 instead of 0 to 3.
  [15:0] TSTPATRX1QOFFSET — Offset value to be used for the first sample for the test pattern data in Q channel Rx channel 0. In this register the naming convention for the 4 Rx channel indices are from 1 to 4 instead of 0 to 3.
0x814 TESTPATTERNRX2QCFG rw
  [31:16] TSTPATRX2QINCR — Value to be added for each successive sample for the test pattern data in Q channel Rx channel 1.
  [15:0] TSTPATRX2QOFFSET — Offset value to be used for the first sample for the test pattern data in Q channel Rx channel 1.
0x818 TESTPATTERNRX3QCFG rw
  [31:16] TSTPATRX3QINCR — Value to be added for each successive sample for the test pattern data in Q channel Rx channel 2
  [15:0] TSTPATRX3QOFFSET — Offset value to be used for the first sample for the test pattern data in Q channel Rx channel 2
0x81C TESTPATTERNRX4QCFG rw
  [31:16] TSTPATRX4QINCR — Value to be added for each successive sample for the test pattern data in Q channel Rx channel 3
  [15:0] TSTPATRX4QOFFSET — Offset value to be used for the first sample for the test pattern data in Q channel Rx channel 3
0x820 TESTPATTERNVLDCFG rw
  [10:8] TSTPATGENEN — Enable for test pattern generator. This is used to Mux with the functional data from BSS. 000 -->Disable, 111-->Enable, Others are reserved.
  [7:0] TSTPATVLDCNT — Number of DSS Interconnect clocks (200 MHz) between successive samples for the test pattern gen.
0x824 ADCBUFCFG1 access per field
  [16] ADCBUFPIPOSEL ro — TI Internal Feature Ping-pong select value from ADC Buffer Packing logic. Even in SW override mode, this register will indicate the ping-pong select signal generated from the ADC Buffer Packing logic and not the override value.
  [15] ADCBUFCONTSTOPPL rw — Stop Pulse for Continuous mode. The data capture will stop once this register is set. Continous mode is expected to be only used for CZ and ADC Buffer Testpattern mode : Its a wspecial access type, write to this field will generate a pulse
  [14] ADCBUFCONTSTRTPL rw — Start Pulse for Continuous mode. The data capture will start from Address 0 once this register is set. All the other configurations like Enable, Sample Count are expected to be programmed before this pulse. Continous mode is expected to be only used for CZ and ADC Buffer Testpattern mode : Its a wspecial access type, write to this field will generate a pulse
  [13] ADCBUFCONTMODEEN rw — Continuous mode enable for ADC Buffer. This is set when a fixed number of samples have to be stored in Ping/Pong and not depend on Chirp time-lines (Eg: Analog Lab characterization to stream out continuous data from DFE). Continous mode is expected to be only used for CZ and ADC Buffer Testpattern mode
  [12] ADCBUFWRITEMODE rw — This needs to be programmed to 0x1 in AR16xx 0 --> Interleaved, 1 --> Non-interleaved
  [11] ADCBUFPIPOOVRVAL rw — TI Internal Feature SW override value for ADC Buffer Ping Pong select
  [10] ADCBUFPIPOOVRCNT rw — TI Internal Feature Override control for ADC Buffer Ping Pong select
  [n+6] RX{n}EN rw (n=0..3) — Enable for Rx{n} write
  [5] ADCBUFIQSWAP rw — 0 --> I is stored in LSB and Q is stored in MSB 1 --> Q is stored in LSB and I is stored in MSB
  [4] ADCBUFRL2CHINTRL rw — TI reserved field. Do not touch
  [3] ADCBUFRLMODECHSEL rw — TI Internal Feature 0 -->I channel, 1 --> Q channel
  [2] ADCBUFREALONLYMODE rw — 0-->Complex Data mode, 1-->Real data mode
  [1] ADCBUFPIPOSELINV rw — TI Internal Feature Inversion control for ADC Buffer Ping-pong select. By default ADC Buffer write starts with Pong write. By setting this bit to 1, it will start from Ping write after reset.
  [0] ADCBUFWRSOURCE rw — TI Internal Feature Write source for ADC Buffer. 0 --> DFE, 1 --> VIN
0x828 ADCBUFCFG1_EXTD rw
  [31:0] ADCBUFINTGENDLY — TI Intenal Feature. No of clocks to delay the ping-pong switch and interrupt generation w.r.t ADC Valid fall pulse. This will enable dithering the DSP activity for successive ping-pong switch cycles. This will not delay the ping pong toggle which will happen immediately after ADC Valid fall.
0x82C ADCBUFCFG2 rw
  [26:16] ADCBUFADDRX1 — 128 bit Address offset to be added to the internal address pointer for Rx1 writes in Non-interleaved mode.
  [10:0] ADCBUFADDRX0 — 128 bit Address offset to be added to the internal address pointer for Rx0 writes in Non-interleaved mode.
0x830 ADCBUFCFG3 rw
  [26:16] ADCBUFADDRX3 — 128 bit Address offset to be added to the internal address pointer for Rx3 writes in Non-interleaved mode.
  [10:0] ADCBUFADDRX2 — 128 bit Address offset to be added to the internal address pointer for Rx2 writes in Non-interleaved mode.
0x834 ADCBUFCFG4 rw
  [30] ADCBUFPNGSELTGLDIS — TI Internal Feature 0 --> Delay Interrupt Gen and Ping/Pong toggle together based on cfg_interrupt_gen_delay, 1 --> Delay only Interrupt Gen based on cfg_interrupt_gen_delay. But toggle Ping/Pong select signal as soon as the write is complete.
  [25:21] ADCBUFNUMCHRPPONG — Number of chirps to be stored in Pong buffer. This register should be programmed with one less than the actual number needed. This is used when data is written to Pong Memory. The value written to this field should be the same as that configured for Ping
  [20:16] ADCBUFNUMCHRPPING — Number of chirps to be stored in Ping buffer. This register should be programmed with one less than the actual number needed. This is used when data is written to Pong Memory. The value written to this field should be the same as that configured for Pong
  [15:0] ADCBUFSAMPCNT — No of samples to store in each Ping and Pong register in continuous mode of ADC Buffer. In real only mode this refers to the number of real samples and in complex mode, this refers to number of complex samples. This refers to the number of samples per channel. This counter increments once for every new sample from DFE (as long as 1 or more channels are enabled). The max allowed value varies depending on other configurations (No of channels enabled and real/complex data). Continous mode is expected to be only used for CZ and ADC Buffer Testpattern mode
0x838 ADCBUFINTGENDITHERDLY rw
  [31:0] ADCBUFINTGENDITHERDLY — TI Internal Feature. Additional dithering delay added on the Chirp Avilable interrupt
0x83C CBUFF_FRAME_START_SEL rw
  [0] sel — writing: 1'b0: selects frame_start from DFE 1'b1: Selects frame_start from chirp_avail (adc capture complete)
0xC00 CQCFG1 rw
  [30:22] CQ2BASEADDR — 128-bit Address offset which inidcates the start address for storing CQ0 (ADC/RxIF Saturation Detection) from the start of CQ memory. This is not the byte address offset but 128 bit address offset
  [21:13] CQ1BASEADDR — 128-bit Address offset which inidcates the start address for storing CQ0 (Signal Image Band Energy detection) from the start of CQ memory. This is not the byte address offset but 128 bit address offset
  [12:4] CQ0BASEADDR — 128-bit Address offset which inidcates the start address for storing CQ0 (Wide Band Energy detection) from the start of CQ memory. This is not the byte address offset but 128 bit address offset
  [3] CQ96BITPACKEN — This is used to pack the CQ data into only the LSB 96 bits of each row of the CQ memory. This can be used in 3 channel mode of LVDS where the ADC data and Chirp Params occupy only LSB 96 bits of each memory row.
  [1:0] CQDATAWIDTH — This is used to appropriately pack the valid CQ data bits in appropriate bits in the CQ memory. 00, 01->Raw 16, 10-->Raw 12, 11-->Raw14
0xC04 CQCFG2 rw
  [17] CQ_CLK_GATE — writing: 1'b0: ungates the clk to CQ logic 1'b1: Gates the clk to CQ logic
  [16] CQPIPOSELVAL — Ping pong select override value for CQ Memory. 1 --> Read access from Chirp Info Slave of DSS Interconnect will be routed to ping memory and write access from CQ_W/DFE write will be routed to pong memory. 0 --> Read access from Chirp Info Slave of DSS Interconnect will be routed to pong memory and write access from CQ_W/DFE write will be routed to ping memory.
  [12] CQPIPOSELCNT — Ping pong select override control for CQ Memory. 0 --> Ping-pong select comes from HW FSM (same as the ping-pong select for ADC Buffer)/DMMCQPINPONSEL 1 --> Ping pong select for CQ memory is taken from SW register (CQPIPOSELVAL)
  [8] CQ2TESTMODEEN — TI Internal Feaure Test Mode enable for CQ2 (ADC/RxIF Saturation). Once enabled, each 8 bit data is same as Addr+1.
  [4] CQ1TESTMODEEN — TI Internal Feaure Test Mode enable for CQ1 (SI). Once enabled, each 16 bit data is same as [2*Addr+1 for the MSB 8 bits and Addr+1 for the LSB 8 bits.
  [0] CQ0TESTMODEEN — TI Internal Feaure Test Mode enable for CQ0 (WBE). Once enabled, each 16 bit data is same as [2*Addr+1 for the MSB 8 bits and Addr+1 for the LSB 8 bits.
{0xC08+4i} CPREG{i} (i=0..15)
  [31:0] CPREG{i} — Chirp Parameters Register {i}. Refer to Chirp Parameter section for more details (DSS_CP)
{0xC48+4i} CH0CPREG{i} (i=0..15)
  [31:0] CH0CPREG{i} — Multi Chirp 0 Parameters Register {i}. Refer to Chirp Parameter section for more details (DSS_CP)
{0xC88+4i} CH1CPREG{i} (i=0..15)
  [31:0] CH1CPREG{i} — Multi Chirp 1 Parameters Register {i}. Refer to Chirp Parameter section for more details (DSS_CP)
{0xCC8+4i} CH2CPREG{i} (i=0..15)
  [31:0] CH2CPREG{i} — Multi Chirp 2 Parameters Register {i}. Refer to Chirp Parameter section for more details (DSS_CP)
{0xD08+4i} CH3CPREG{i} (i=0..15)
  [31:0] CH3CPREG{i} — Multi Chirp 3 Parameters Register {i}. Refer to Chirp Parameter section for more details (DSS_CP)
{0xD48+4i} CH4CPREG{i} (i=0..15)
  [31:0] CH4CPREG{i} — Multi Chirp 4 Parameters Register {i}. Refer to Chirp Parameter section for more details (DSS_CP)
{0xD88+4i} CH5CPREG{i} (i=0..15)
  [31:0] CH5CPREG{i} — Multi Chirp 5 Parameters Register {i}. Refer to Chirp Parameter section for more details (DSS_CP)
{0xDC8+4i} CH6CPREG{i} (i=0..15)
  [31:0] CH6CPREG{i} — Multi Chirp 6 Parameters Register {i}. Refer to Chirp Parameter section for more details (DSS_CP)
{0xE08+4i} CH7CPREG{i} (i=0..15)
  [31:0] CH7CPREG{i} — Multi Chirp 7 Parameters Register {i}. Refer to Chirp Parameter section for more details (DSS_CP)
0xE48 CH01_HIL_CP_OVERRIDE rw
  [31:16] chirp1 — Override data used for Chirp1. data[11:0] is used for overriding chirp number data[15:12] is used for overriding chirp profile index
  [15:0] chirp0 — Override data used for Chirp0. data[11:0] is used for overriding chirp number data[15:12] is used for overriding chirp profile index
0xE4C CH23_HIL_CP_OVERRIDE rw
  [31:16] chirp3 — Override data used for Chirp3. data[11:0] is used for overriding chirp number data[15:12] is used for overriding chirp profile index
  [15:0] chirp2 — Override data used for Chirp2. data[11:0] is used for overriding chirp number data[15:12] is used for overriding chirp profile index
0xE50 CH45_HIL_CP_OVERRIDE rw
  [31:16] chirp5 — Override data used for Chirp5. data[11:0] is used for overriding chirp number data[15:12] is used for overriding chirp profile index
  [15:0] chirp4 — Override data used for Chirp4. data[11:0] is used for overriding chirp number data[15:12] is used for overriding chirp profile index
0xE54 CH67_HIL_CP_OVERRIDE rw
  [31:16] chirp7 — Override data used for Chirp7. data[11:0] is used for overriding chirp number data[15:12] is used for overriding chirp profile index
  [15:0] chirp6 — Override data used for Chirp6. data[11:0] is used for overriding chirp number data[15:12] is used for overriding chirp profile index
0xE58 CH_HIL_CP_OVERRIDE rw
  [15:0] chirp — Override data used for Chirp. data[11:0] is used for overriding chirp number data[15:12] is used for overriding chirp profile index
{0xFD0+4i} HW_SPARE_RW{i} rw (i=0..3)
  [31:0] hw_spare_rw{i} — Reserved for HW R&D
{0xFE0+4i} HW_SPARE_RO{i} (i=0..3)
  [31:0] hw_spare_ro{i} — Reserved for HW R&D
0xFF0 HW_SPARE_WPH rw
  [31:0] hw_spare_wph — Reserved for HW R&D
0xFF4 HW_SPARE_REC rw
  [n] hw_spare_rec{n} (n=0..31) — Reserved for HW R&D
0x1008 LOCK0_KICK0 rw — - KICK0 component
  [31:0] ?
0x100C LOCK0_KICK1 rw — - KICK1 component
  [31:0] ?
0x1010 intr_raw_status rw — Interrupt Raw Status/Set Register
  [3] ? — Proxy0 access violation error. Raw status is read. Write a 1 to set the status. Writing a 0 has no effect.
  [2] ? — Kick access violation error. Raw status is read. Write a 1 to set the status. Writing a 0 has no effect.
  [1] ? — Addressing violation error. Raw status is read. Write a 1 to set the status. Writing a 0 has no effect.
  [0] ? — Protection violation error. Raw status is read. Write a 1 to set the status. Writing a 0 has no effect.
0x1014 intr_enabled_status_clear rw — Interrupt Enabled Status/Clear register
  [3] ? — Proxy0 access violation error. Enabled status is read. Write a 1 to clear the status. Writing a 0 has no effect.
  [2] ? — Kick access violation error. Enabled status is read. Write a 1 to clear the status. Writing a 0 has no effect.
  [1] ? — Addressing violation error. Enabled status is read. Write a 1 to clear the status. Writing a 0 has no effect.
  [0] ? — Protection violation error. Enabled status is read. Write a 1 to clear the status. Writing a 0 has no effect.
0x1018 intr_enable rw — Interrupt Enable register
  [3] ? — Proxy0 access violation error enable. Write a 1 to set the enable. Writing a 0 has no effect.
  [2] ? — Kick access violation error enable. Write a 1 to set the enable. Writing a 0 has no effect.
  [1] ? — Addressing violation error enable. Write a 1 to set the enable. Writing a 0 has no effect.
  [0] ? — Protection violation error enable. Write a 1 to set the enable. Writing a 0 has no effect.
0x101C intr_enable_clear rw — Interrupt Enable Clear register
  [3] ? — Proxy0 access violation error enable clear. Write a 1 to clear the enable. Writing a 0 has no effect.
  [2] ? — Kick access violation error enable clear. Write a 1 to clear the enable. Writing a 0 has no effect.
  [1] ? — Addressing violation error enable clear. Write a 1 to clear the enable. Writing a 0 has no effect.
  [0] ? — Protection violation error enable clear. Write a 1 to clear the enable. Writing a 0 has no effect.
0x1020 eoi rw
  [7:0] ? — EOI vector value. Write this with interrupt distribution value in the chip.
0x1024 fault_address
  [31:0] ? — Fault Address.
0x1028 fault_type_status
  [6] ? — Non-secure access.
  [5:0] ? — Fault Type 10_0000 = Supervisor read fault - priv = 1 dir = 1 dtype != 1 01_0000 = Supervisor write fault - priv = 1 dir = 0 00_1000 = Supervisor execute fault - priv = 1 dir = 1 dtype = 1 00_0100 = User read fault - priv = 0 dir = 1 dtype = 1 00_0010 = User write fault - priv = 0 dir = 0 00_0001 = User execute fault - priv = 0 dir = 1 dtype = 1 00_0000 = No fault
0x102C fault_attr_status — Fault Attribute Status register
  [31:20] ? — XID.
  [19:8] ? — Route ID.
  [7:0] ? — Privilege ID.
0x1030 fault_clear wo
  [0] ? — Fault clear. Writing a 1 clears the current fault. Writing a 0 has no effect.
